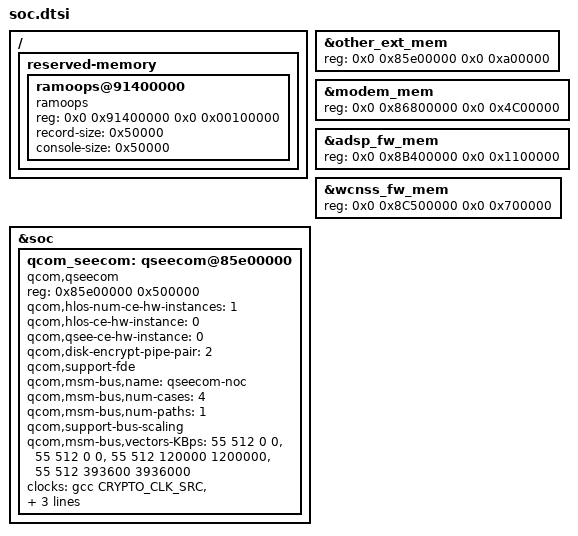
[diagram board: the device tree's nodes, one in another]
&other_ext_mem {
	reg = <0x0 0x85e00000 0x0 0xa00000>;
};

&modem_mem {
	reg = <0x0 0x86800000 0x0 0x4C00000>;
};

&adsp_fw_mem {
	reg = <0x0 0x8B400000 0x0 0x1100000>;
};

&wcnss_fw_mem {
	reg = <0x0 0x8C500000 0x0 0x700000>;
};

/ {
	reserved-memory {
		ramoops@91400000 {
			compatible = "ramoops";
			reg = <0x0 0x91400000 0x0 0x00100000>;
			record-size = <0x50000>;
			console-size = <0x50000>;
		};
	};
};

&soc {
	/delete-node/ qseecom@84a00000;
	qcom_seecom: qseecom@85e00000 {
		compatible = "qcom,qseecom";
		reg = <0x85e00000 0x500000>;
		reg-names = "secapp-region";
		qcom,hlos-num-ce-hw-instances = <1>;
		qcom,hlos-ce-hw-instance = <0>;
		qcom,qsee-ce-hw-instance = <0>;
		qcom,disk-encrypt-pipe-pair = <2>;
		qcom,support-fde;
		qcom,msm-bus,name = "qseecom-noc";
		qcom,msm-bus,num-cases = <4>;
		qcom,msm-bus,num-paths = <1>;
		qcom,support-bus-scaling;
		qcom,msm-bus,vectors-KBps =
			<55 512 0 0>,
			<55 512 0 0>,
			<55 512 120000 1200000>,
			<55 512 393600 3936000>;
		clocks = <&gcc CRYPTO_CLK_SRC>,
			<&gcc GCC_CRYPTO_CLK>,
			<&gcc GCC_CRYPTO_AHB_CLK>,
			<&gcc GCC_CRYPTO_AXI_CLK>;
		clock-names = "core_clk_src", "core_clk",
			"iface_clk", "bus_clk";
		qcom,ce-opp-freq = <100000000>;
	};
};
